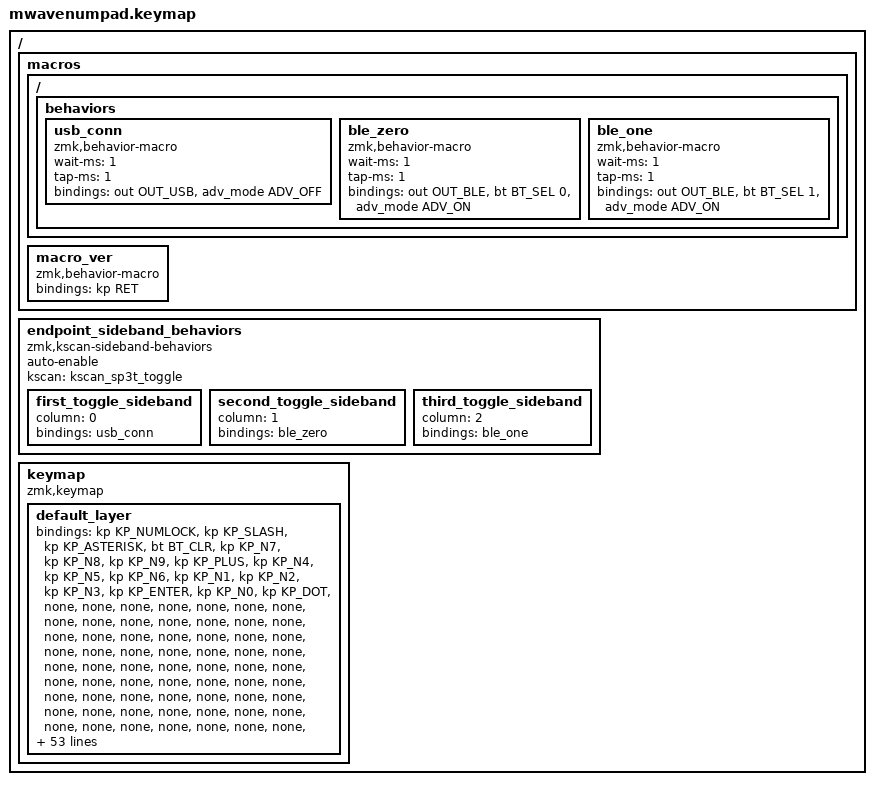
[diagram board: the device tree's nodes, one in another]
#include <behaviors.dtsi>
#include <dt-bindings/zmk/keys.h>
#include <dt-bindings/zmk/bt.h>
#include <dt-bindings/zmk/outputs.h>
#include <dt-bindings/zmk/backlight.h>
#include <dt-bindings/advertising_mode.h>

#include <behaviors/advertising_mode.dtsi>

/ {
  macros {
    ZMK_MACRO(usb_conn,
        wait-ms = <1>;
        tap-ms = <1>;
        bindings = <&out OUT_USB &adv_mode ADV_OFF>;
    )
    ZMK_MACRO(ble_zero,
        wait-ms = <1>;
        tap-ms = <1>;
        bindings = <&out OUT_BLE &bt BT_SEL 0 &adv_mode ADV_ON>;
    )
    ZMK_MACRO(ble_one,
        wait-ms = <1>;
        tap-ms = <1>;
        bindings = <&out OUT_BLE &bt BT_SEL 1 &adv_mode ADV_ON>;
    )
    macro_ver: macro_ver {
      compatible = "zmk,behavior-macro";
      #binding-cells = <0>;
      bindings = <&kp RET>;
    };
  };

  endpoint_sideband_behaviors {
      auto-enable;
      compatible = "zmk,kscan-sideband-behaviors";
      kscan = <&kscan_sp3t_toggle>;

      first_toggle_sideband: first_toggle_sideband {
          column = <0>;
          bindings = <&usb_conn>;
      };

      second_toggle_sideband: second_toggle_sideband {
          column = <1>;
          bindings = <&ble_zero>;
      };

      third_toggle_sideband: third_toggle_sideband {
          column = <2>;
          bindings = <&ble_one>;
      };
  };

  keymap {
    compatible = "zmk,keymap";
    default_layer {
      bindings = <
        &kp KP_NUMLOCK &kp KP_SLASH &kp KP_ASTERISK &bt BT_CLR
        &kp KP_N7      &kp KP_N8    &kp KP_N9       &kp KP_PLUS
        &kp KP_N4      &kp KP_N5    &kp KP_N6 
        &kp KP_N1      &kp KP_N2    &kp KP_N3       &kp KP_ENTER 
               &kp KP_N0            &kp KP_DOT  
        &none &none &none &none &none &none &none &none &none &none &none &none &none &none &none &none &none &none &none &none &none &none &none &none &none &none &none &none &none &none &none &none &none &none &none &none 
&none &none &none &none &none &none &none &none &none &none &none &none &none &none &none &none &none &none &none &none &none &none &none &none &none &none &none &none &none &none &none &none &none &none &none &none 
&none &none &none &none &none &none &none &none &none &none &none &none &none &none &none &none &none &none &none &none &none &none &none &none &none &none &none &none &none &none &none &none &none &none &none &none 
&none &none &none &none &none &none &none &none &none &none &none &none &none &none &none &none &none &none &none &none &none &none &none &none &none &none &none &none &none &none &none &none &none &none &none &none 
&none &none &none &none &none &none &none &none &none &none &none &none &none &none &none &none &none &none &none &none &none &none &none &none &none &none &none &none &none &none &none &none &none &none &none &none 
&none &none &none &none &none &none &none &none &none &none &none &none &none &none &none &none &none &none &none &none &none &none &none &none &none &none &none &none &none &none &none &none &none &none &none &none 
&none &none &none &none &none &none &none &none &none &none &none &none &none &none &none &none &none &none &none &none &none &none &none &none &none &none &none &none &none &none &none &none &none &none &none &none 
&none &none &none &none &none &none &none &none &none &none &none &none &none &none &none &none &none &none &none &none &none &none &none &none &none &none &none &none &none &none &none &none &none &none &none &none 
&none &none &none &none &none &none &none &none &none &none &none &none &none &none &none &none &none &none &none &none &none &none &none &none &none &none &none &none &none &none &none &none &none &none &none &none 
&none &none &none &none &none &none &none &none &none &none &none &none &none &none &none &none &none &none &none &none &none &none &none &none &none &none &none &none &none &none &none &none &none &none &none &none 
&none &none &none &none &none &none &none &none &none &none &none &none &none &none &none &none &none &none &none &none &none &none &none &none &none &none &none &none &none &none &none &none &none &none &none &none 
&none &none &none &none &none &none &none &none &none &none &none &none &none &none &none &none &none &none &none &none &none &none &none &none &none &none &none &none &none &none &none &none &none &none &none &none 

      >;
    };
  };
};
